# RN821X_RN721X_SOC_B register map
File version: v1.0.6
CPU: CM0 r0p0, little endian, no MPU, no FPU, 3 interrupt priority bits
Registers are 32-bit, read-write, reset 0x0 unless marked. A register's access mark holds for its fields unless they carry their own. Offsets are from the block's base; [hi:lo] are bit positions; {n}, {i} and the like mark numbered series; 'fields as' and 'values as' point back to an identical list.

## GPIO
Base 0x50000000
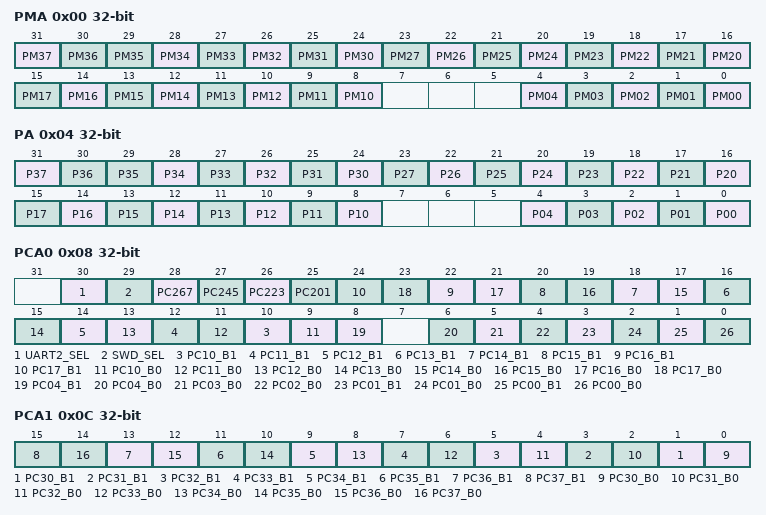
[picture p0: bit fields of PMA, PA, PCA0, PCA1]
0x00 PMA — port A mode register
  [all] fields
    0=OUT (use as output mode); 1=IN (use as input mode)
  [31] PM37 — P37 input(1)/output(0) mode state bi
  [30] PM36 — P36 input(1)/output(0) mode state bit
  [n-6] PM{n} (n=30..35) — P{n} input(1)/output(0) mode selection bit
  [n-4] PM{n} (n=20..27) — P{n} input(1)/output(0) mode selection bit
  [n-2] PM{n} (n=10..17) — P{n} input(1)/output(0) mode selection bit
  [n] PM{n:02} (n=0..4) — P{n:02} input(1)/output(0) mode selection bit
0x04 PA — port A data register
  [31] P37 ro — port A P37 data bit
  [30] P36 ro — port A P36 data bit
  [n-6] P{n} (n=30..35) — port A P{n} data bit
  [n-4] P{n} (n=20..27) — port A P{n} data bit
  [n-2] P{n} (n=10..17) — port A P{n} data bit
  [n] P{n:02} (n=0..4) — port A P{n:02} data bit
0x08 PCA0 — port A mode config register 0
  [30] UART2_SEL — UART2 selection bits
    0=PC245 (select P24/P25 as UART2, when P24/P25 PC245 properly cfg as UART2); 1=PC0_1 (select P00/P01 as UART2, when P00/P01 PC00 PC01 properly cfg as UART2)
  [29] SWD_SEL — SWD selection bit
    0=OTH (when PCA3.PC245(PCA3[20]) = 0, P24 P25 function define by PCA0.PCA0_PC245); 1=P245 (when PCA3.PC245(PCA3[20]) = 0, use P24 as SWDCLK and P25 as SWDIO)
  [28] PC267 — P26 and P27 mode cfg bit
    0=IO (P26 and P27 use as general IO, available when PCA3.PC267(PCA3[27]) = 0); 1=UART3 (P26(RX3) and P27(TX3) use as UART3, available when PCA3.PC267(PCA3[27]) = 0)
  [27] PC245 — P24 and P25 mode cfg bit
    0=IO (P24 and P25 use as general IO, available when PCA3.PC245(PCA3[20]) = 0 and PCA0.SWD_SEL(PCA0[29]) =0); 1=UART2 (P24(RX2) and P25(TX2) use as UART2, available when PCA3.PC245(PCA3[20]) = 0 and PCA0.SWD_SEL(PCA0[29]) =0)
  [26] PC223 — P22 and P23 mode cfg bit
    0=IO (P22 and P23 use as general IO, available when PCA3.PC223(PCA3[13]) = 0); 1=UART1 (P22(RX1) and P23(TX1) use as UART1, available when PCA3.PC223(PCA3[13]) = 0)
  [25] PC201 — P20 and P21 mode cfg bit
    0=IO (P20 and P21 use as general IO, available when PCA3.PC201(PCA3[6]) = 0); 1=UART0 (P20(RX0) and P21(TX0) use as UART0, available when PCA3.PC201(PCA3[6]) = 0)
  [2n-10] PC{n}_B1 (n=10..17) — PC{n} mode cfg bit1, detail info please read manual PCA0.PC{n}(PCA0[{2n-10}:{2n-11}])
  [2n-11] PC{n}_B0 (n=10..17) — PC{n} mode cfg bit0, detail info please read manual PCA0.PC{n}(PCA0[{2n-10}:{2n-11}])
  [8] PC04_B1 — PC04 mode cfg bit1, detail info please read manual PCA0.PC04(PCA0[6])
  [6] PC04_B0 — PC04 mode cfg bit0, detail info please read manual PCA0.PC04(PCA0[6])
  [5] PC03_B0 — PC03 mode cfg bit0, detail info please read manual PCA0.PC03(PCA0[5])
  [4] PC02_B0 — PC02 mode cfg bit0, detail info please read manual PCA0.PC02(PCA0[4])
  [3] PC01_B1 — PC01 mode cfg bit1, detail info please read manual PCA0.PC01(PCA0[3:2])
  [2] PC01_B0 — PC01 mode cfg bit0, detail info please read manual PCA0.PC01(PCA0[3:2])
  [1] PC00_B1 — PC00 mode cfg bit1, detail info please read manual PCA0.PC00(PCA0[1:0])
  [0] PC00_B0 — PC00 mode cfg bit0, detail info please read manual PCA0.PC00(PCA0[1:0])
0x0C PCA1 — port A mode config register 1
  [2n-59] PC{n}_B1 (n=30..37) — PC{n} mode cfg bit1, detail info please read manual PCA1.PC{n}(PCA1[{2n-59}:{2n-60}])
  [2n-60] PC{n}_B0 (n=30..37) — PC{n} mode cfg bit0, detail info please read manual PCA1.PC{n}(PCA1[{2n-59}:{2n-60}])
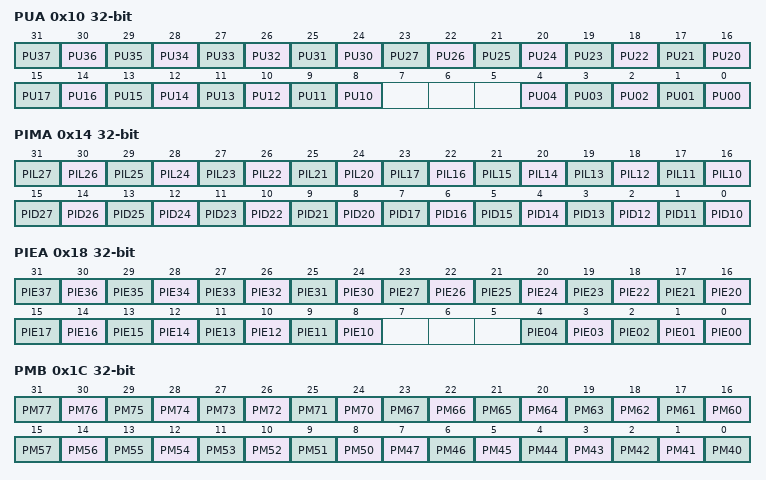
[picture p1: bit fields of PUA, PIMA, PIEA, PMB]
0x10 PUA — port A pull-up config register
  [all] fields
    0=NUL (do not pull-up); 1=PU (pull-up)
  [n-6] PU{n} (n=30..37) — P{n} pull up cfg bit (=0 do not pull up, =1 pull up)
  [n-4] PU{n} (n=20..27) — P{n} pull up cfg bit (=0 do not pull up, =1 pull up)
  [n-2] PU{n} (n=10..17) — P{n} pull up cfg bit (=0 do not pull up, =1 pull up)
  [n] PU{n:02} (n=0..4) — P{n:02} pull up cfg bit (=0 do not pull up, =1 pull up)
0x14 PIMA — port A input config register
  [n+4] PIL{n} (n=20..27) — P{n} input cfg bit
    0=CMOS (select as CMOS input mode, Vil=0.3VCC Vih = 0.7VCC); 1=TTL (select as TTL input mode, Vil=0.16VCC Vih = 0.4VCC)
  [n+6] PIL{n} (n=10..17) — P{n} input cfg bit
    values as PIL20
  [n-12] PID{n} (n=20..27) — P{n} output mode cfg bit
    0=NORM (select as normal output mode); 1=NCH (select as N channel open drain output)
  [n-10] PID{n} (n=10..17) — P{n} output mode cfg bit
    values as PID20
0x18 PIEA — port A input enable register
  [n-6] PIE{n} (n=30..37) — P{n} input disbale bit (=1 disable input, =0 enable input)
  [n-4] PIE{n} (n=20..27) — P{n} input disbale bit (=1 disable input, =0 enable input)
  [n-2] PIE{n} (n=10..17) — P{n} input disbale bit (=1 disable input, =0 enable input)
  [n] PIE{n:02} (n=1..4) — P{n:02} input disbale bit (=1 disable input, =0 enable input)
  [0] PIE00 — P00 input disbale bit (=1 disable input, =0 enable input)
    1=DIS (disable input); 0=EN (enable input)
0x1C PMB — port B mode register
  [n-46] PM{n} (n=70..77) — P{n} input/output cfg bit (=0 output mode, =1 input mode)
  [n-44] PM{n} (n=60..67) — P{n} input/output cfg bit (=0 output mode, =1 input mode)
  [n-42] PM{n} (n=50..57) — P{n} input/output cfg bit (=0 output mode, =1 input mode)
  [n-40] PM{n} (n=41..47) — P{n} input/output cfg bit (=0 output mode, =1 input mode)
  [0] PM40 — P40 input/output cfg bit (=0 output mode, =1 input mode)
    0=OUT (use as output mode); 1=IN (use as input mode)
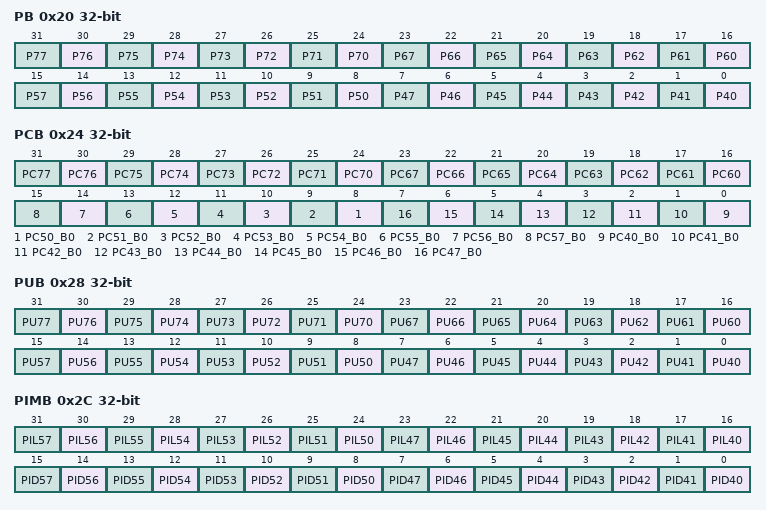
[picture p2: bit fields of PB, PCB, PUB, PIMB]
0x20 PB — port B data register
  [n-46] P{n} (n=70..77) — port B P{n} data bit
  [n-44] P{n} (n=60..67) — port B P{n} data bit
  [n-42] P{n} (n=50..57) — port B P{n} data bit
  [n-40] P{n} (n=40..47) — port B P{n} data bit
0x24 PCB — port B mode config register
  [n-46] PC{n} (n=70..77) — P{n} mode cfg bit
    0=IO (use as general IO); 1=LCD (use as LCD)
  [n-44] PC{n} (n=60..67) — P{n} mode cfg bit
    0=IO (use as general IO); 1=LCD (use as LCD)
  [n-42] PC{n}_B0 (n=50..57) — PC{n} mode cfg bit0, detail info please read manual PCB[{n-42}]
  [n-40] PC{n}_B0 (n=40..47) — PC{n} mode cfg bit0, detail info please read manual PCB[{n-40}]
0x28 PUB — port B pull-up/down config register
  [n-46] PU{n} (n=70..77) — P{n} pull-down enable bit (=1 enable pull-down, =0 do not enable pul down)
    0=NUL (do not pull-down); 1=DOWN (pull-down)
  [n-44] PU{n} (n=60..67) — P{n} pull-down enable bit (=1 enable pull-down, =0 do not enable pul down)
    0=NUL (do not pull-down); 1=DOWN (pull-down)
  [n-42] PU{n} (n=50..57) — P{n} pull-up enable bit (=1 enable pull-up, =0 do not enable pull up)
    0=NUL (do not pull-up); 1=UP (pull-up)
  [n-40] PU{n} (n=40..47) — P{n} pull-up enable bit (=1 enable pull-up, =0 do not enable pull up)
    0=NUL (do not pull-up); 1=UP (pull-up)
0x2C PIMB — port B input config register
  [n-26] PIL{n} (n=50..57) — P{n} input mode cfg bit
    values as PIMA.PIL20
  [n-24] PIL{n} (n=40..47) — P{n} input mode cfg bit
    values as PIMA.PIL20
  [n-42] PID{n} (n=50..57) — P{n} output mode cfg bit
    values as PIMA.PID20
  [n-40] PID{n} (n=40..47) — P{n} output mode cfg bit
    values as PIMA.PID20
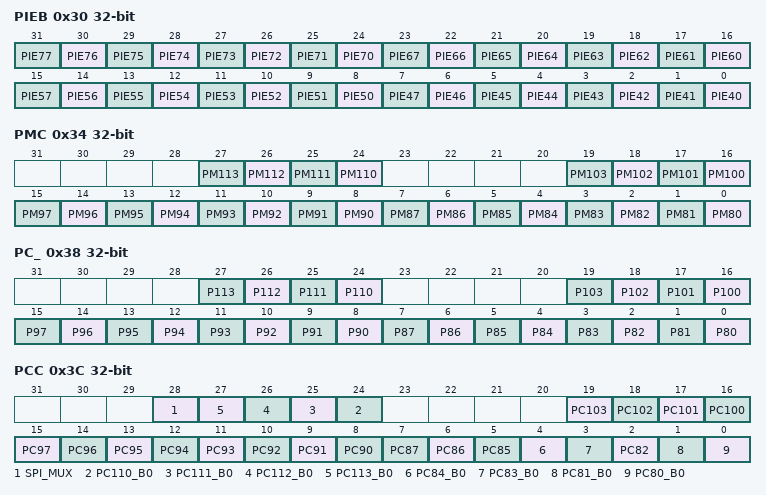
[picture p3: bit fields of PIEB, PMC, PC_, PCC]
0x30 PIEB — port B input enable register
  [all] fields
    1=DIS (do not use as input); 0=EN (use as input)
  [n-46] PIE{n} (n=70..77) — P{n} input disable bit (=1 disable input, =0 enable input)
  [n-44] PIE{n} (n=60..67) — P{n} input disable bit (=1 disable input, =0 enable input)
  [n-42] PIE{n} (n=50..57) — P{n} input disable bit (=1 disable input, =0 enable input)
  [n-40] PIE{n} (n=40..47) — P{n} input disable bit (=1 disable input, =0 enable input)
0x34 PMC — port C mode register
  [all] fields
    0=OUT (use as output mode); 1=IN (use as input mode)
  [n-86] PM{n} (n=110..113) — P{n} input/output cfg bit (=0 output mode, =1 input mode)
  [n-84] PM{n} (n=100..103) — P{n} input/output cfg bit (=0 output mode, =1 input mode)
  [n-82] PM{n} (n=90..97) — P{n} input/output cfg bit (=0 output mode, =1 input mode)
  [n-80] PM{n} (n=80..87) — P{n} input/output cfg bit (=0 output mode, =1 input mode)
0x38 PC_ — port C data register
  [n-86] P{n} (n=110..113) — port C P{n} data bit
  [n-84] P{n} (n=100..103) — port C P{n} data bit
  [n-82] P{n} (n=90..97) — port C P{n} data bit
  [n-80] P{n} (n=80..87) — port C P{n} data bit
0x3C PCC — port C mode config register
  [28] SPI_MUX — SPI0 pin defination bit
    0=P4 (select P50/P51/P46/P47 as SPI0); 1=P11 (select P110/P111/P112/P113 as SPI0)
  [n-86] PC{n}_B0 (n=110..113) — PC{n} mode cfg bit0, detail info please read manual PCC[{n-86}]
  [n-84] PC{n} (n=100..103) — PC{n} mode cfg bit
    0=IO (select as general IO); 1=LCD (select as LCD)
  [n-82] PC{n} (n=90..97) — PC{n} mode cfg bit
    0=IO (select as general IO); 1=LCD (select as LCD)
  [7] PC87 — PC87 mode cfg bit
    0=IO (select as general IO); 1=LCD (select as LCD)
  [6] PC86 — PC86 mode cfg bit
    0=IO (select as general IO); 1=LCD (select as LCD)
  [5] PC85 — PC85 mode cfg bit
    0=IO (select as general IO); 1=LCD (select as LCD)
  [4] PC84_B0 — PC84 mode cfg bit0, detail info please read manual PCC[4]
  [3] PC83_B0 — PC83 mode cfg bit0, detail info please read manual PCC[3]
  [2] PC82 — PC82 mode cfg bit
    0=IO (select as general IO); 1=LCD (select as LCD)
  [1] PC81_B0 — PC81 mode cfg bit0, detail info please read manual PCC[1]
  [0] PC80_B0 — PC80 mode cfg bit0, detail info please read manual PCC[0]
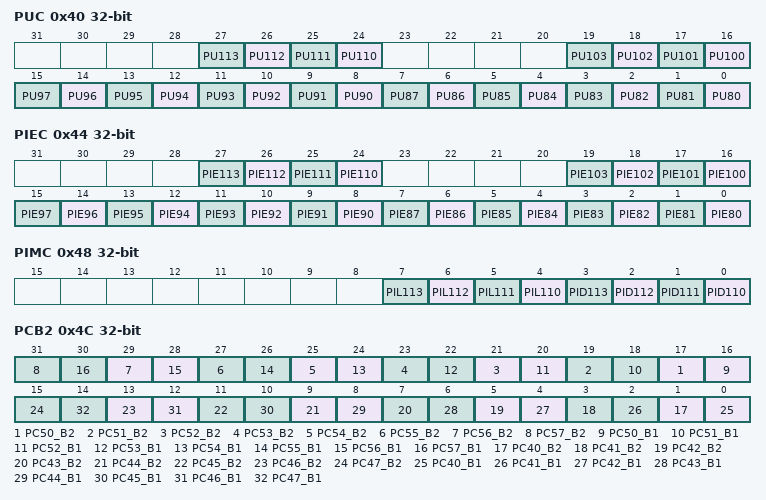
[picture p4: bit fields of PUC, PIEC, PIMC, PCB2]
0x40 PUC — port C pull-up/down config register
  [n-86] PU{n} (n=110..113) — P{n} pull up enable bit(=1 enable pull-up ,=0 do not enable pull-up)
    0=NUL (do not pull-up); 1=UP (pull-up)
  [n-84] PU{n} (n=100..103) — P{n} pull down enable bit(=1 enable pull-down ,=0 do not enable pull-down)
    0=NUL (do not pull-up); 1=UP (pull-up)
  [n-82] PU{n} (n=90..97) — P{n} pull down enable bit(=1 enable pull-down ,=0 do not enable pull-down)
    0=NUL (do not pull-down); 1=DOWN (pull-down)
  [n-80] PU{n} (n=80..87) — P{n} pull down enable bit(=1 enable pull-down ,=0 do not enable pull-down)
    0=NUL (do not pull-down); 1=DOWN (pull-down)
0x44 PIEC — port C input enable register
  [all] fields
    1=DIS (disable input); 0=EN (enable input)
  [n-86] PIE{n} (n=110..113) — P{n} input disable bit(=1 disable input, =0 enable input)
  [n-84] PIE{n} (n=100..103) — P{n} input disable bit(=1 disable input, =0 enable input)
  [n-82] PIE{n} (n=90..97) — P{n} input disable bit(=1 disable input, =0 enable input)
  [n-80] PIE{n} (n=80..87) — P{n} input disable bit(=1 disable input, =0 enable input)
0x48 PIMC — port C input config register
  [n-106] PIL{n} (n=110..113) — P{n} input mode cfg bit
    values as PIMA.PIL20
  [n-110] PID{n} (n=110..113) — P{n} output mode cfg bit
    values as PIMA.PID20
0x4C PCB2 — port B mode config register 2
  [2n-83] PC{n}_B2 (n=50..57) — PC{n} mode cfg bit2, detail info please read manual
  [2n-84] PC{n}_B1 (n=50..57) — PC{n} mode cfg bit1, detail info please read manual
  [2n-79] PC{n}_B2 (n=40..47) — PC{n} mode cfg bit2, detail info please read manual
  [2n-80] PC{n}_B1 (n=40..47) — PC{n} mode cfg bit1, detail info please read manual
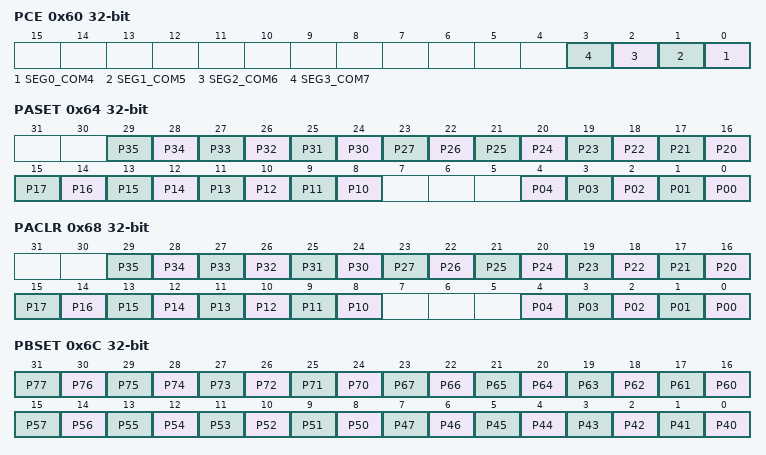
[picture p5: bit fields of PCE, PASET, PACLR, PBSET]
0x60 PCE — SEGCOM mode selection register
  [all] fields
    0=SEG (select as SEG); 1=COM (select as COM)
  [n] SEG{n}_COM{n+4} (n=0..3) — SEG{n}_COM{n+4} mode selection bit
0x64 PASET — port A state set register
  [all] fields
    0=NUL (no effection); 1=HIGH (set as high level)
  [n-6] P{n} (n=30..35) — PA P{n} state set bit
  [n-4] P{n} (n=20..27) — PA P{n} state set bit
  [n-2] P{n} (n=10..17) — PA P{n} state set bit
  [n] P{n:02} (n=0..4) — PA P{n:02} state set bit
0x68 PACLR — port A state clean register
  [all] fields
    0=NUL (no effection); 1=CLR (clean pin state, set low level output)
  [n-6] P{n} (n=30..35) — PA P{n} state clean bit
  [n-4] P{n} (n=20..27) — PA P{n} state clean bit
  [n-2] P{n} (n=10..17) — PA P{n} state clean bit
  [n] P{n:02} (n=0..4) — PA P{n:02} state clean bit
0x6C PBSET — port B state set register
  [all] fields
    0=NUL (no effection); 1=HIGH (set as high level)
  [n-46] P{n} (n=70..77) — PB P{n} state set bit
  [n-44] P{n} (n=60..67) — PB P{n} state set bit
  [n-42] P{n} (n=50..57) — PB P{n} state set bit
  [n-40] P{n} (n=40..47) — PB P{n} state set bit
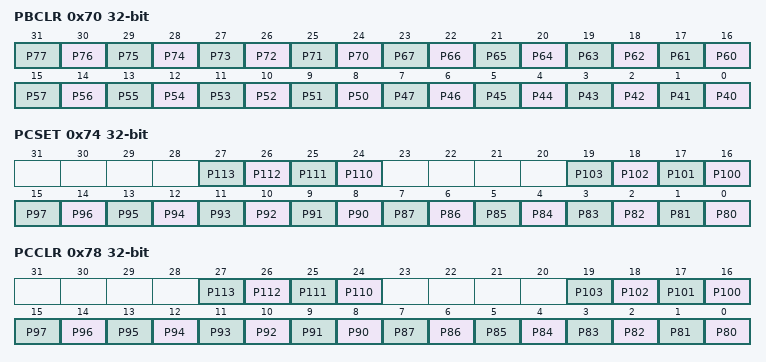
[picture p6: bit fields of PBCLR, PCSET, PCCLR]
0x70 PBCLR — port B state clean register
  [all] fields
    values as the fields of PACLR
  [n-46] P{n} (n=70..77) — PB P{n} state clean bit
  [n-44] P{n} (n=60..67) — PB P{n} state clean bit
  [n-42] P{n} (n=50..57) — PB P{n} state clean bit
  [n-40] P{n} (n=40..47) — PB P{n} state clean bit
0x74 PCSET — port C state set register
  [all] fields
    0=NUL (no effection); 1=HIGH (set as high level)
  [n-86] P{n} (n=110..113) — PC P{n} state set bit
  [n-84] P{n} (n=100..103) — PC P{n} state set bit
  [n-82] P{n} (n=90..97) — PC P{n} state set bit
  [n-80] P{n} (n=80..87) — PC P{n} state set bit
0x78 PCCLR — port C state clean register
  [all] fields
    values as the fields of PACLR
  [n-86] P{n} (n=110..113) — PC P{n} state clean bit
  [n-84] P{n} (n=100..103) — PC P{n} state clean bit
  [n-82] P{n} (n=90..97) — PC P{n} state clean bit
  [n-80] P{n} (n=80..87) — PC P{n} state clean bit
